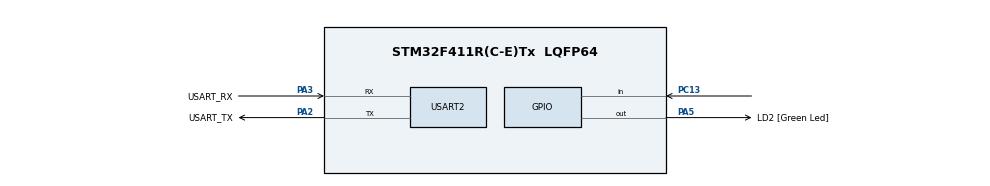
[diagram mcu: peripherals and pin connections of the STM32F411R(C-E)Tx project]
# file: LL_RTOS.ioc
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FREERTOS.BinarySemaphores01=go_sema,Dynamic,NULL
FREERTOS.Tasks01=defaultTask,24,128,StartDefaultTask,Default,NULL,Dynamic,NULL,NULL;led_task,8,128,StartTask02,Default,NULL,Dynamic,NULL,NULL;button_task,8,128,StartTask03,Default,NULL,Dynamic,NULL,NULL
FREERTOS.configUSE_NEWLIB_REENTRANT=1
Mcu.Family=STM32F4
Mcu.Name=STM32F411R(C-E)Tx
Mcu.Package=LQFP64
NVIC.PriorityGroup=NVIC_PRIORITYGROUP_4
NVIC.TIM5_IRQn=true\:15\:0\:false\:false\:true\:false\:false\:true\:true
NVIC.TimeBase=TIM5_IRQn
NVIC.TimeBaseIP=TIM5
PA13.GPIO_Label=TMS
PA13.Mode=Serial_Wire
PA13.Signal=SYS_JTMS-SWDIO
PA14.GPIO_Label=TCK
PA14.Mode=Serial_Wire
PA14.Signal=SYS_JTCK-SWCLK
PA2.GPIO_Label=USART_TX
PA2.Mode=Asynchronous
PA2.Signal=USART2_TX
PA3.GPIO_Label=USART_RX
PA3.Mode=Asynchronous
PA3.Signal=USART2_RX
PA5.GPIO_Label=LD2 [Green Led]
PA5.Signal=GPIO_Output
PB3.GPIO_Label=SWO
PB3.Signal=SYS_JTDO-SWO
PC13-ANTI_TAMP.GPIO_PuPd=GPIO_PULLUP
PC13-ANTI_TAMP.Signal=GPIO_Input
PC14-OSC32_IN.Mode=LSE-External-Oscillator
PC14-OSC32_IN.Signal=RCC_OSC32_IN
PC15-OSC32_OUT.Mode=LSE-External-Oscillator
PC15-OSC32_OUT.Signal=RCC_OSC32_OUT
PH0\ -\ OSC_IN.Mode=HSE-External-Clock-Source
PH0\ -\ OSC_IN.Signal=RCC_OSC_IN
PH1\ -\ OSC_OUT.Mode=HSE-External-Clock-Source
PH1\ -\ OSC_OUT.Signal=RCC_OSC_OUT
ProjectManager.HeapSize=0x200
ProjectManager.StackSize=0x400
ProjectManager.TargetToolchain=STM32CubeIDE
RCC.48MHZClocksFreq_Value=84000000
RCC.AHBFreq_Value=84000000
RCC.APB1CLKDivider=RCC_HCLK_DIV2
RCC.APB1Freq_Value=42000000
RCC.APB1TimFreq_Value=84000000
RCC.APB2Freq_Value=84000000
RCC.APB2TimFreq_Value=84000000
RCC.CortexFreq_Value=84000000
RCC.FLatency-AdvancedSettings=FLASH_LATENCY_2
RCC.HCLKFreq_Value=84000000
RCC.HSE_VALUE=8000000
RCC.HSI_VALUE=16000000
RCC.PLLN=336
RCC.PLLP=RCC_PLLP_DIV4
RCC.SYSCLKFreq_VALUE=84000000
RCC.SYSCLKSource=RCC_SYSCLKSOURCE_PLLCLK
RCC.VCOOutputFreq_Value=336000000
USART2.VirtualMode=VM_ASYNC
VP_FREERTOS_VS_CMSIS_V2.Mode=CMSIS_V2
VP_SYS_VS_tim5.Mode=TIM5
board=NUCLEO-F411RE

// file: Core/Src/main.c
/* USER CODE BEGIN Header */
/**
  ******************************************************************************
  * @file           : main.c
  * @brief          : Main program body
  ******************************************************************************
  * @attention
  *
  * Copyright (c) 2024 STMicroelectronics.
  * All rights reserved.
  *
  * This software is licensed under terms that can be found in the LICENSE file
  * in the root directory of this software component.
  * If no LICENSE file comes with this software, it is provided AS-IS.
  *
  ******************************************************************************
  */
/* USER CODE END Header */
#include "main.h"
#include "cmsis_os.h"

/* USER CODE BEGIN Includes */
#include <stdbool.h>
/* USER CODE END Includes */

/* Definitions for defaultTask */
osThreadId_t defaultTaskHandle;
const osThreadAttr_t defaultTask_attributes = {
  .name = "defaultTask",
  .stack_size = 128 * 4,
  .priority = (osPriority_t) osPriorityNormal,
};
/* Definitions for led_task */
osThreadId_t led_taskHandle;
const osThreadAttr_t led_task_attributes = {
  .name = "led_task",
  .stack_size = 128 * 4,
  .priority = (osPriority_t) osPriorityLow,
};
/* Definitions for button_task */
osThreadId_t button_taskHandle;
const osThreadAttr_t button_task_attributes = {
  .name = "button_task",
  .stack_size = 128 * 4,
  .priority = (osPriority_t) osPriorityLow,
};
/* Definitions for go_sema */
osSemaphoreId_t go_semaHandle;
const osSemaphoreAttr_t go_sema_attributes = {
  .name = "go_sema"
};

void SystemClock_Config(void);
static void MX_GPIO_Init(void);
static void MX_USART2_UART_Init(void);
void StartDefaultTask(void *argument);
void StartTask02(void *argument);
void StartTask03(void *argument);

int main(void)
{

  /* MCU Configuration--------------------------------------------------------*/

  /* Reset of all peripherals, Initializes the Flash interface and the Systick. */
  HAL_Init();

  /* Configure the system clock */
  SystemClock_Config();

  /* Initialize all configured peripherals */
  MX_GPIO_Init();
  MX_USART2_UART_Init();

  /* Init scheduler */
  osKernelInitialize();

  /* Create the semaphores(s) */
  /* creation of go_sema */
  go_semaHandle = osSemaphoreNew(1, 0, &go_sema_attributes);

  /* Create the thread(s) */
  /* creation of defaultTask */
  defaultTaskHandle = osThreadNew(StartDefaultTask, NULL, &defaultTask_attributes);

  /* creation of led_task */
  led_taskHandle = osThreadNew(StartTask02, NULL, &led_task_attributes);

  /* creation of button_task */
  button_taskHandle = osThreadNew(StartTask03, NULL, &button_task_attributes);

  /* Start scheduler */
  osKernelStart();

  /* We should never get here as control is now taken by the scheduler */

  /* Infinite loop */
  while (1)
  {

  }
}

void SystemClock_Config(void)
{
  LL_FLASH_SetLatency(LL_FLASH_LATENCY_2);
  while(LL_FLASH_GetLatency()!= LL_FLASH_LATENCY_2)
  {
  }
  LL_PWR_SetRegulVoltageScaling(LL_PWR_REGU_VOLTAGE_SCALE1);
  LL_RCC_HSI_SetCalibTrimming(16);
  LL_RCC_HSI_Enable();

   /* Wait till HSI is ready */
  while(LL_RCC_HSI_IsReady() != 1)
  {

  }
  LL_RCC_PLL_ConfigDomain_SYS(LL_RCC_PLLSOURCE_HSI, LL_RCC_PLLM_DIV_16, 336, LL_RCC_PLLP_DIV_4);
  LL_RCC_PLL_Enable();

   /* Wait till PLL is ready */
  while(LL_RCC_PLL_IsReady() != 1)
  {

  }
  while (LL_PWR_IsActiveFlag_VOS() == 0)
  {
  }
  LL_RCC_SetAHBPrescaler(LL_RCC_SYSCLK_DIV_1);
  LL_RCC_SetAPB1Prescaler(LL_RCC_APB1_DIV_2);
  LL_RCC_SetAPB2Prescaler(LL_RCC_APB2_DIV_1);
  LL_RCC_SetSysClkSource(LL_RCC_SYS_CLKSOURCE_PLL);

   /* Wait till System clock is ready */
  while(LL_RCC_GetSysClkSource() != LL_RCC_SYS_CLKSOURCE_STATUS_PLL)
  {

  }
  LL_SetSystemCoreClock(84000000);

   /* Update the time base */
  if (HAL_InitTick (TICK_INT_PRIORITY) != HAL_OK)
  {
    Error_Handler();
  }
  LL_RCC_SetTIMPrescaler(LL_RCC_TIM_PRESCALER_TWICE);
}

static void MX_USART2_UART_Init(void)
{

  LL_USART_InitTypeDef USART_InitStruct = {0};

  LL_GPIO_InitTypeDef GPIO_InitStruct = {0};

  /* Peripheral clock enable */
  LL_APB1_GRP1_EnableClock(LL_APB1_GRP1_PERIPH_USART2);

  LL_AHB1_GRP1_EnableClock(LL_AHB1_GRP1_PERIPH_GPIOA);
  /**USART2 GPIO Configuration
  PA2   ------> USART2_TX
  PA3   ------> USART2_RX
  */
  GPIO_InitStruct.Pin = USART_TX_Pin|USART_RX_Pin;
  GPIO_InitStruct.Mode = LL_GPIO_MODE_ALTERNATE;
  GPIO_InitStruct.Speed = LL_GPIO_SPEED_FREQ_VERY_HIGH;
  GPIO_InitStruct.OutputType = LL_GPIO_OUTPUT_PUSHPULL;
  GPIO_InitStruct.Pull = LL_GPIO_PULL_NO;
  GPIO_InitStruct.Alternate = LL_GPIO_AF_7;
  LL_GPIO_Init(GPIOA, &GPIO_InitStruct);

  USART_InitStruct.BaudRate = 115200;
  USART_InitStruct.DataWidth = LL_USART_DATAWIDTH_8B;
  USART_InitStruct.StopBits = LL_USART_STOPBITS_1;
  USART_InitStruct.Parity = LL_USART_PARITY_NONE;
  USART_InitStruct.TransferDirection = LL_USART_DIRECTION_TX_RX;
  USART_InitStruct.HardwareFlowControl = LL_USART_HWCONTROL_NONE;
  USART_InitStruct.OverSampling = LL_USART_OVERSAMPLING_16;
  LL_USART_Init(USART2, &USART_InitStruct);
  LL_USART_ConfigAsyncMode(USART2);
  LL_USART_Enable(USART2);

}

static void MX_GPIO_Init(void)
{
  LL_GPIO_InitTypeDef GPIO_InitStruct = {0};

  /* GPIO Ports Clock Enable */
  LL_AHB1_GRP1_EnableClock(LL_AHB1_GRP1_PERIPH_GPIOC);
  LL_AHB1_GRP1_EnableClock(LL_AHB1_GRP1_PERIPH_GPIOH);
  LL_AHB1_GRP1_EnableClock(LL_AHB1_GRP1_PERIPH_GPIOA);
  LL_AHB1_GRP1_EnableClock(LL_AHB1_GRP1_PERIPH_GPIOB);

  /**/
  LL_GPIO_ResetOutputPin(LD2_GPIO_Port, LD2_Pin);

  /**/
  GPIO_InitStruct.Pin = LL_GPIO_PIN_13;
  GPIO_InitStruct.Mode = LL_GPIO_MODE_INPUT;
  GPIO_InitStruct.Pull = LL_GPIO_PULL_UP;
  LL_GPIO_Init(GPIOC, &GPIO_InitStruct);

  /**/
  GPIO_InitStruct.Pin = LD2_Pin;
  GPIO_InitStruct.Mode = LL_GPIO_MODE_OUTPUT;
  GPIO_InitStruct.Speed = LL_GPIO_SPEED_FREQ_LOW;
  GPIO_InitStruct.OutputType = LL_GPIO_OUTPUT_PUSHPULL;
  GPIO_InitStruct.Pull = LL_GPIO_PULL_NO;
  LL_GPIO_Init(LD2_GPIO_Port, &GPIO_InitStruct);

}

void StartDefaultTask(void *argument)
{
  for(;;)
  {
    osDelay(1);
  }
}

void StartTask02(void *argument)
{
  /* USER CODE BEGIN StartTask02 */
  /*
   	   Without using num, when you press the button the LED toggle.
   	   If you hold the button down, the LED will blink for the time
   	   you continue to press.

   	   With num (uncomment all the section where there is num), when
   	   the button is pressed, the LED blink 11 times and then stop,
   	   indipendently from the status button.
  */
  //uint32_t num = 0;
  osDelay(1);
  /* Infinite loop */
  for(;;)
  {
	/*if(num == 0)*/ osSemaphoreAcquire(go_semaHandle, osWaitForever);
	LL_GPIO_TogglePin(LD2_GPIO_Port, LD2_Pin);
	//num++;
	osDelay(1000);
	//if(num > 10) num = 0;
  }
  /* USER CODE END StartTask02 */
}

void StartTask03(void *argument)
{
  /* USER CODE BEGIN StartTask03 */
  /* Infinite loop */
  for(;;)
  {
	if (!LL_GPIO_IsInputPinSet(GPIOC, LL_GPIO_PIN_13)) osSemaphoreRelease(go_semaHandle);
	osDelay(250);	// Debouncing
  }
  /* USER CODE END StartTask03 */
}

void HAL_TIM_PeriodElapsedCallback(TIM_HandleTypeDef *htim)
{
  if (htim->Instance == TIM5) {
    HAL_IncTick();
  }
}

void Error_Handler(void)
{
  __disable_irq();
  while (1)
  {
  }
}
